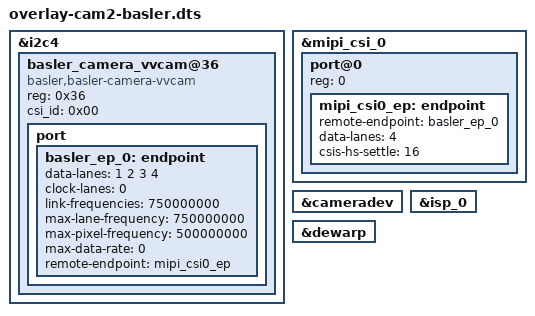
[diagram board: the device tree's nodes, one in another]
/*
 * Copyright (C) 2022 Avnet Embedded GmbH
 *
 * This program is free software; you can redistribute it and/or
 * modify it under the terms of the GNU General Public License as
 * published by the Free Software Foundation version 2.
 *
 * This program is distributed "as is" WITHOUT ANY WARRANTY of any
 * kind, whether express or implied; without even the implied warranty
 * of MERCHANTABILITY or FITNESS FOR A PARTICULAR PURPOSE.  See the
 * GNU General Public License for more details.
 */

/dts-v1/;
/plugin/;

#include <dt-bindings/clock/imx8mp-clock.h>

/ {
	fragment@3200 {
		target = <&i2c4>;
		__overlay__ {
			#address-cells = <1>;
			#size-cells = <0>;
			basler_camera_vvcam@36 {
				compatible = "basler,basler-camera-vvcam", "basler-camera-vvcam";
				reg = <0x36>;
				csi_id = <0x00>;
				status = "okay";
				port {
					basler_ep_0: endpoint {
						data-lanes = <1 2 3 4>;
						clock-lanes = <0>;
						link-frequencies = /bits/ 64 <750000000>;
						max-lane-frequency = /bits/ 64 <750000000>;
						max-pixel-frequency = /bits/ 64 <500000000>;
						max-data-rate = /bits/ 64 <0>;
						remote-endpoint = <&mipi_csi0_ep>;
					};
				};
			};
		};
	};

	fragment@3201 {
		target = <&mipi_csi_0>;
		__overlay__ {
			#address-cells = <1>;
			#size-cells = <0>;
			status = "okay";
			port@0 {
				reg = <0>;
				mipi_csi0_ep: endpoint {
					remote-endpoint = <&basler_ep_0>;
					data-lanes = <4>;
					csis-hs-settle = <16>;
				};
			};
		};
	};

	fragment@3202 {
		target = <&cameradev>;
		__overlay__ {
			status = "okay";
		};
	};

	fragment@3203 {
		target = <&isp_0>;
		__overlay__ {
			status = "okay";
		};
	};

	fragment@3204 {
		target = <&dewarp>;
		__overlay__ {
			status = "okay";
		};
	};
};
